AUTOSAR XML (schema 3-2-1)
package /SeatHeatingController
  swc implementation SeatHeatingControllerImplementation: behavior=SeatHeatingControllerbehavioral
  internal behavior SeatHeatingControllerbehavioral: component=SeatHeating
    operation invoked event opInvokedEventSeatHeatingController: start-on-event=SeatHeatingControllerSetPosition, operation=RegulatorPosition.SetPosition
    timing event timingEventSeatHeatingController: start-on-event=SeatHeatingControllerMain, period=0.0
    inter runnable variable InetrRunVar: type=Int32, communication-approach=IMPLICIT
    runnable SeatHeatingControllerMain: can-be-invoked-concurrently=true, read-variable=InetrRunVar
      data read access dataReadAccess_1: data-element=LeftSeatStatus.PassengerOnSeat
      data read access dataReadAccess_2: data-element=RightSeatStatus.PassengerOnSeat
      sync call syncCallPoint_1: operation=HeaterLevels.SetHeat
    runnable SeatHeatingControllerSetPosition: can-be-invoked-concurrently=true, written-variable=InetrRunVar
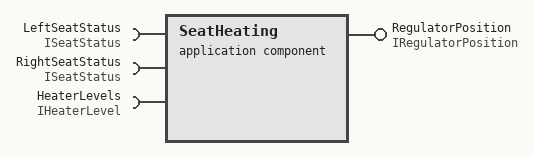
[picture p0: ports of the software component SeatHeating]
  application software component type SeatHeating
    require port LeftSeatStatus: required-interface=ISeatStatus
    require port RightSeatStatus: required-interface=ISeatStatus
    provide port RegulatorPosition: provided-interface=IRegulatorPosition
    require port HeaterLevels: required-interface=IHeaterLevel
